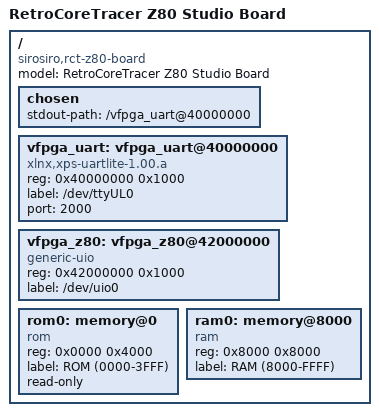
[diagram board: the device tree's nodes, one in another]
/dts-v1/;

/ {
    model = "RetroCoreTracer Z80 Studio Board";
    compatible = "sirosiro,rct-z80-board";

    #address-cells = <1>;
    #size-cells = <1>;

    chosen {
        stdout-path = "/vfpga_uart@40000000";
    };

    /* 標準 UART: CLI / テレメトリ通信用 */
    vfpga_uart: vfpga_uart@40000000 {
        compatible = "xlnx,xps-uartlite-1.00.a";
        reg = <0x40000000 0x1000>;
        label = "/dev/ttyUL0";
        port = <2000>;
    };

    /* Z80 Tracer Control Register (UIO) */
    vfpga_z80: vfpga_z80@42000000 {
        compatible = "generic-uio";
        reg = <0x42000000 0x1000>;
        label = "/dev/uio0";
    };

    /* Z80 Memory Map Definition (Single Source of Truth) */
    rom0: memory@0 {
        compatible = "rom";
        reg = <0x0000 0x4000>;
        label = "ROM (0000-3FFF)";
        read-only;
    };

    ram0: memory@8000 {
        device_type = "memory";
        compatible = "ram";
        reg = <0x8000 0x8000>;
        label = "RAM (8000-FFFF)";
    };
};
